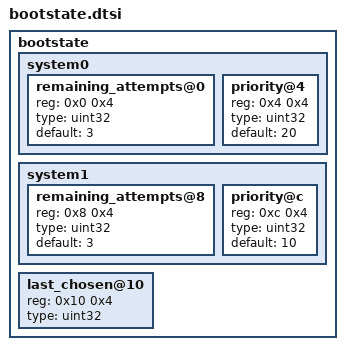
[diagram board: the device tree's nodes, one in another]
// SPDX-License-Identifier: (GPL-2.0+ OR BSD-3-Clause)

bootstate {
	#address-cells = <1>;
	#size-cells = <1>;

	system0 {
		#address-cells = <1>;
		#size-cells = <1>;

		remaining_attempts@0 {
			reg = <0x0 0x4>;
			type = "uint32";
			default = <3>;
		};

		priority@4 {
			reg = <0x4 0x4>;
			type = "uint32";
			default = <20>;
		};
	};

	system1 {
		#address-cells = <1>;
		#size-cells = <1>;

		remaining_attempts@8 {
			reg = <0x8 0x4>;
			type = "uint32";
			default = <3>;
		};

		priority@c {
			reg = <0xc 0x4>;
			type = "uint32";
			default = <10>;
		};
	};

	last_chosen@10 {
		reg = <0x10 0x4>;
		type = "uint32";
	};
};
